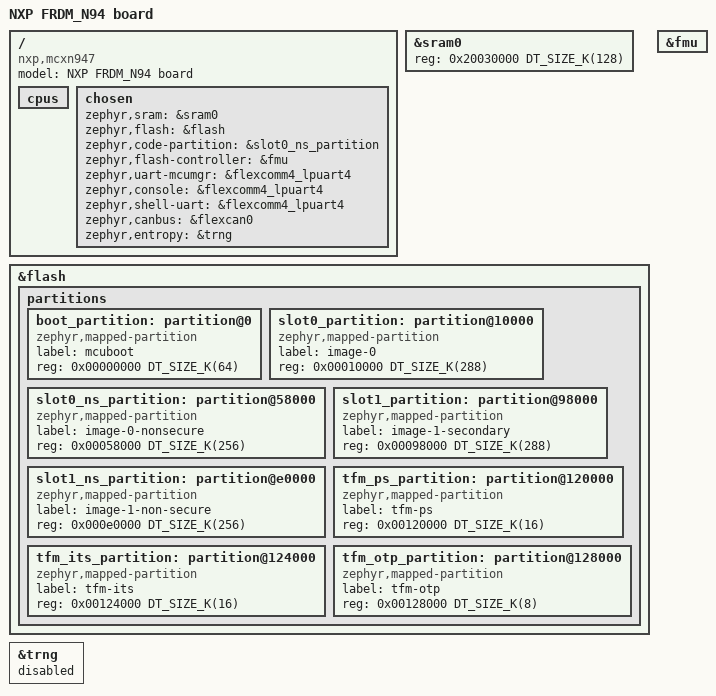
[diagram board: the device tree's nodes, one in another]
/*
 * Copyright 2025 NXP
 *
 * SPDX-License-Identifier: Apache-2.0
 */

/dts-v1/;

#include <nxp/mcx/mcxn/nxp_mcxn947_ns.dtsi>
#include "frdm_mcxn947_mcxn947_cpu0.dtsi"

/ {
	model = "NXP FRDM_N94 board";
	compatible = "nxp,mcxn947", "nxp,mcx";

	cpus {
		/delete-node/ cpu@1;
	};

	chosen {
		zephyr,sram = &sram0;
		zephyr,flash = &flash;
		zephyr,code-partition = &slot0_ns_partition;
		zephyr,flash-controller = &fmu;
		zephyr,uart-mcumgr = &flexcomm4_lpuart4;
		zephyr,console = &flexcomm4_lpuart4;
		zephyr,shell-uart = &flexcomm4_lpuart4;
		zephyr,canbus = &flexcan0;
		zephyr,entropy = &trng;
	};
};

/*
 * frdm_mcxn947_mcxn947_cpu0.dtsi allocates the first 320K of sram0 to cpu0.
 * Of that, the first 192K are owned by the secure image; only the remaining
 * 128K are available to this non-secure image.
 */
&sram0 {
	reg = <0x20030000 DT_SIZE_K(128)>;
};

&flash {
	/delete-node/ partitions;

	partitions {
		#address-cells = <1>;
		#size-cells = <1>;
		ranges;

		/*
		 * All partition sizes must be aligned to the flash memory sector size (8 KB).
		 *
		 * This flash layout must exactly match the upstream TF-M layout defined in
		 * the platform-specific `flash_layout.h`. Any modification to the layout
		 * must be applied consistently in both `flash_layout.h` and this file.
		 *
		 * BL2 / MCUBoot
		 */
		boot_partition: partition@0 {
			compatible = "zephyr,mapped-partition";
			label = "mcuboot";
			reg = <0x00000000 DT_SIZE_K(64)>;  /* 64 KB */
		};

		/* Secure image - primary */
		slot0_partition: partition@10000 {
			compatible = "zephyr,mapped-partition";
			label = "image-0";
			reg = <0x00010000 DT_SIZE_K(288)>;  /* 288 KB */
		};

		/* Non-secure image - primary */
		slot0_ns_partition: partition@58000 {
			compatible = "zephyr,mapped-partition";
			label = "image-0-nonsecure";
			reg = <0x00058000 DT_SIZE_K(256)>;  /* 256 KB */
		};

		/* Secure image - secondary */
		slot1_partition: partition@98000 {
			compatible = "zephyr,mapped-partition";
			label = "image-1-secondary";
			reg = <0x00098000 DT_SIZE_K(288)>;  /* 288 KB */
		};

		/* Non-secure image - secondary */
		slot1_ns_partition: partition@e0000 {
			compatible = "zephyr,mapped-partition";
			label = "image-1-non-secure";
			reg = <0x000e0000 DT_SIZE_K(256)>;  /* 256 KB */
		};

		/* Protected Storage (PS) */
		tfm_ps_partition: partition@120000 {
			compatible = "zephyr,mapped-partition";
			label = "tfm-ps";
			reg = <0x00120000 DT_SIZE_K(16)>;   /* 16 KB */
		};

		/* Internal Trusted Storage (ITS) */
		tfm_its_partition: partition@124000 {
			compatible = "zephyr,mapped-partition";
			label = "tfm-its";
			reg = <0x00124000 DT_SIZE_K(16)>;   /* 16 KB */
		};

		/* OTP / NV counters */
		tfm_otp_partition: partition@128000 {
			compatible = "zephyr,mapped-partition";
			label = "tfm-otp";
			reg = <0x00128000 DT_SIZE_K(8)>;    /* 8 KB */
		};
	};
};

&fmu {
	status = "okay";
};

&trng {
	/* Disable TRNG in NS to avoid auto-enabling csprng_available option */
	status = "disabled";
};
